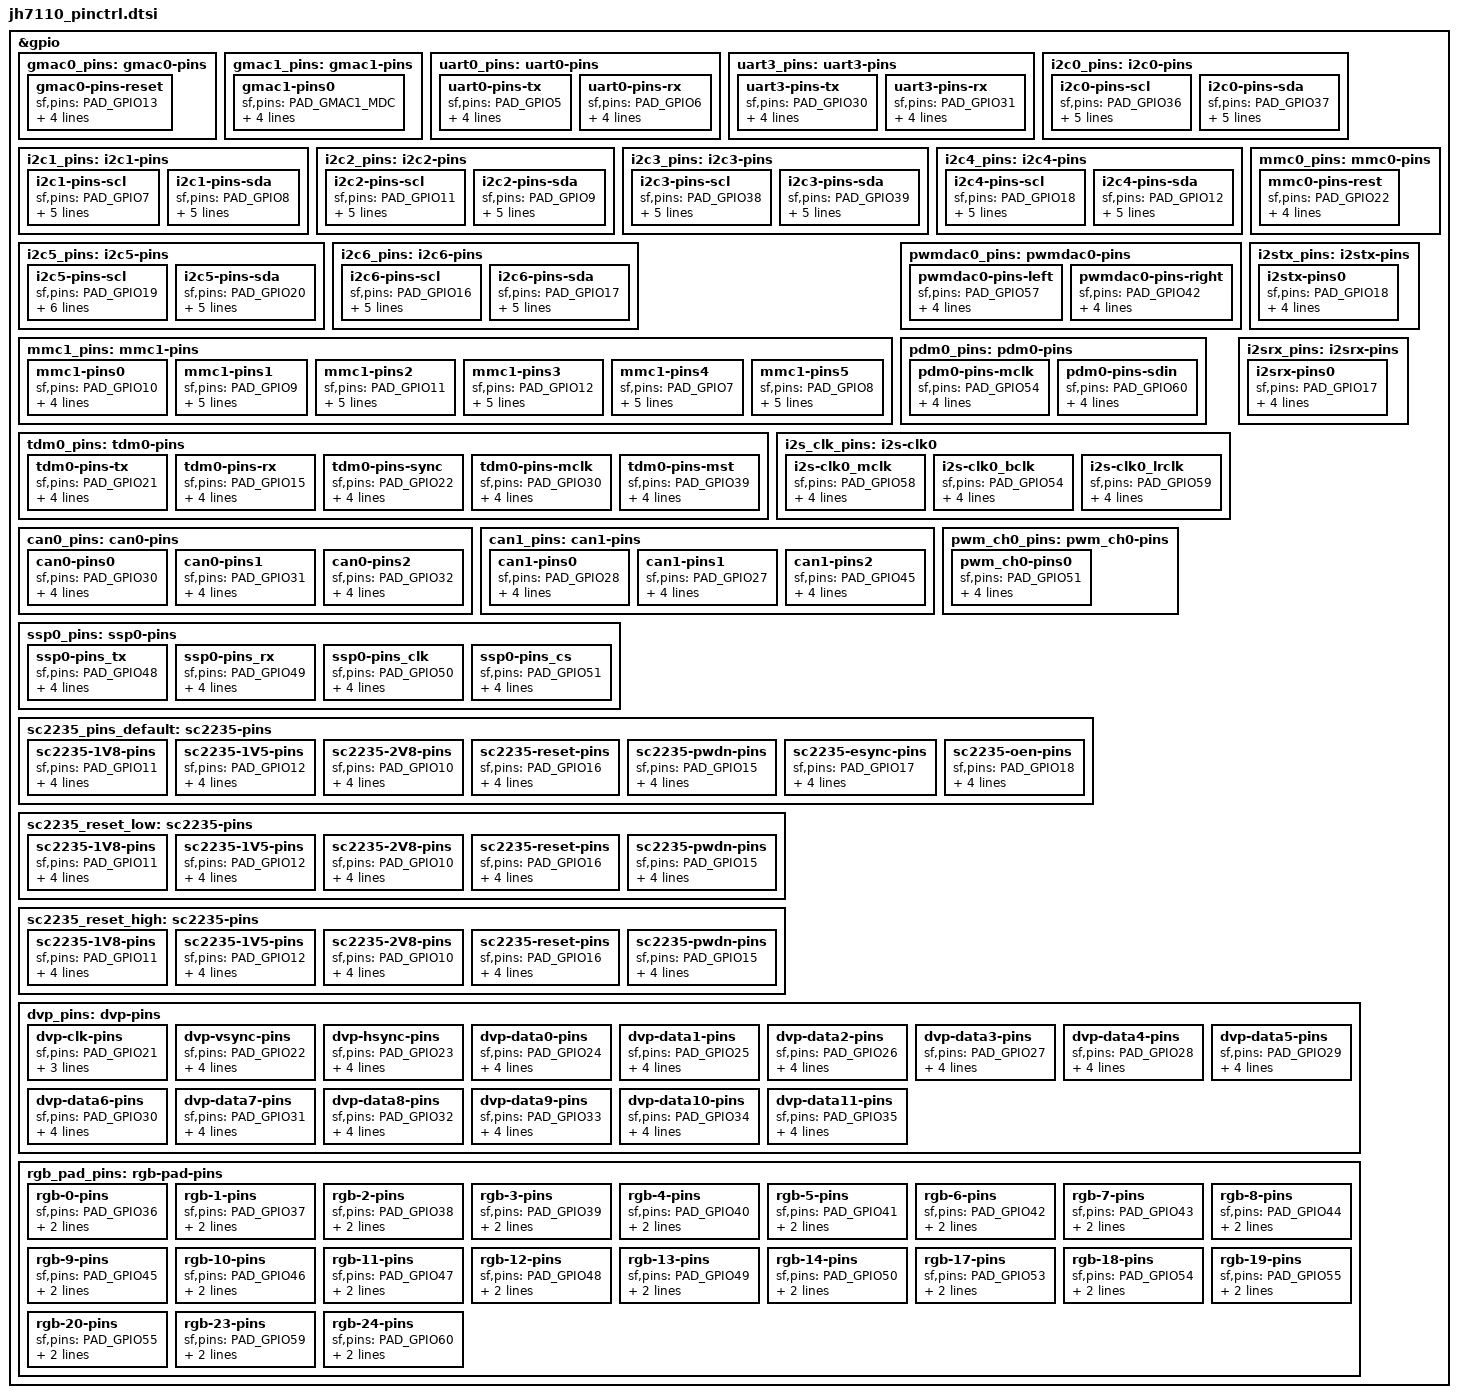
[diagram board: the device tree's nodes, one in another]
// SPDX-License-Identifier: GPL-2.0 OR MIT
/*
 * Copyright (C) 2022 StarFive Technology Co., Ltd.
 */

#include <dt-bindings/gpio/gpio.h>
#include <dt-bindings/pinctrl/starfive,jh7110-pinfunc.h>

&gpio {
	gmac0_pins: gmac0-pins {
		gmac0-pins-reset {
			sf,pins = <PAD_GPIO13>;
			sf,pinmux = <PAD_GPIO13_FUNC_SEL 0>;
			sf,pin-ioconfig = <IO(GPIO_IE(1)|(GPIO_PU(1)))>;
			sf,pin-gpio-dout = <GPO_HIGH>;
			sf,pin-gpio-doen = <OEN_LOW>;
		};
	};

	gmac1_pins: gmac1-pins {
		gmac1-pins0 {
			sf,pins = <PAD_GMAC1_MDC>;
			sf,pin-ioconfig = <IO(GPIO_IE(1)|GPIO_SMT(1)|GPIO_DS(3))>;
			sf,pin-syscon = <PADCFG_PAD_GMAC1_MDC_SYSCON IO_3_3V>;
		};
	};

	uart0_pins: uart0-pins {
		uart0-pins-tx {
			sf,pins = <PAD_GPIO5>;
			sf,pinmux = <PAD_GPIO5_FUNC_SEL 0>;
			sf,pin-ioconfig = <IO(GPIO_IE(1)|GPIO_DS(3))>;
			sf,pin-gpio-dout = <GPO_UART0_SOUT>;
			sf,pin-gpio-doen = <OEN_LOW>;
		};

		uart0-pins-rx {
			sf,pins = <PAD_GPIO6>;
			sf,pinmux = <PAD_GPIO6_FUNC_SEL 0>;
			sf,pin-ioconfig = <IO(GPIO_IE(1)|GPIO_PU(1))>;
			sf,pin-gpio-doen = <OEN_HIGH>;
			sf,pin-gpio-din =  <GPI_UART0_SIN>;
		};
	};

	uart3_pins: uart3-pins {
		uart3-pins-tx {
			sf,pins = <PAD_GPIO30>;
			sf,pinmux = <PAD_GPIO30_FUNC_SEL 0>;
			sf,pin-ioconfig = <IO(GPIO_IE(1)|GPIO_DS(3))>;
			sf,pin-gpio-dout = <GPO_UART3_SOUT>;
			sf,pin-gpio-doen = <OEN_LOW>;
		};

		uart3-pins-rx {
			sf,pins = <PAD_GPIO31>;
			sf,pinmux = <PAD_GPIO31_FUNC_SEL 0>;
			sf,pin-ioconfig = <IO(GPIO_IE(1)|GPIO_PU(1))>;
			sf,pin-gpio-doen = <OEN_HIGH>;
			sf,pin-gpio-din =  <GPI_UART3_SIN>;
		};
	};

	i2c0_pins: i2c0-pins {
		i2c0-pins-scl {
			sf,pins = <PAD_GPIO36>;
			sf,pinmux = <PAD_GPIO36_FUNC_SEL 0>;
			sf,pin-ioconfig = <IO(GPIO_IE(1)|(GPIO_PU(1)))>;
			sf,pin-gpio-dout = <GPO_LOW>;
			sf,pin-gpio-doen = <OEN_I2C0_IC_CLK_OE>;
			sf,pin-gpio-din =  <GPI_I2C0_IC_CLK_IN_A>;
		};

		i2c0-pins-sda {
			sf,pins = <PAD_GPIO37>;
			sf,pinmux = <PAD_GPIO37_FUNC_SEL 0>;
			sf,pin-ioconfig = <IO(GPIO_IE(1)|(GPIO_PU(1)))>;
			sf,pin-gpio-dout = <GPO_LOW>;
			sf,pin-gpio-doen = <OEN_I2C0_IC_DATA_OE>;
			sf,pin-gpio-din =  <GPI_I2C0_IC_DATA_IN_A>;
		};
	};

	i2c1_pins: i2c1-pins {
		i2c1-pins-scl {
			sf,pins = <PAD_GPIO7>;
			sf,pinmux = <PAD_GPIO7_FUNC_SEL 0>;
			sf,pin-ioconfig = <IO(GPIO_IE(1)|(GPIO_PU(1)))>;
			sf,pin-gpio-dout = <GPO_LOW>;
			sf,pin-gpio-doen = <OEN_I2C1_IC_CLK_OE>;
			sf,pin-gpio-din =  <GPI_I2C1_IC_CLK_IN_A>;
		};

		i2c1-pins-sda {
			sf,pins = <PAD_GPIO8>;
			sf,pinmux = <PAD_GPIO8_FUNC_SEL 0>;
			sf,pin-ioconfig = <IO(GPIO_IE(1)|(GPIO_PU(1)))>;
			sf,pin-gpio-dout = <GPO_LOW>;
			sf,pin-gpio-doen = <OEN_I2C1_IC_DATA_OE>;
			sf,pin-gpio-din =  <GPI_I2C1_IC_DATA_IN_A>;
		};
	};

	i2c2_pins: i2c2-pins {
		i2c2-pins-scl {
			sf,pins = <PAD_GPIO11>;
			sf,pinmux = <PAD_GPIO11_FUNC_SEL 0>;
			sf,pin-ioconfig = <IO(GPIO_IE(1)|(GPIO_PU(1)))>;
			sf,pin-gpio-dout = <GPO_LOW>;
			sf,pin-gpio-doen = <OEN_I2C2_IC_CLK_OE>;
			sf,pin-gpio-din =  <GPI_I2C2_IC_CLK_IN_A>;
		};

		i2c2-pins-sda {
			sf,pins = <PAD_GPIO9>;
			sf,pinmux = <PAD_GPIO9_FUNC_SEL 0>;
			sf,pin-ioconfig = <IO(GPIO_IE(1)|(GPIO_PU(1)))>;
			sf,pin-gpio-dout = <GPO_LOW>;
			sf,pin-gpio-doen = <OEN_I2C2_IC_DATA_OE>;
			sf,pin-gpio-din =  <GPI_I2C2_IC_DATA_IN_A>;
		};
	};

	i2c3_pins: i2c3-pins {
		i2c3-pins-scl {
			sf,pins = <PAD_GPIO38>;
			sf,pinmux = <PAD_GPIO38_FUNC_SEL 0>;
			sf,pin-ioconfig = <IO(GPIO_IE(1)|(GPIO_PU(1)))>;
			sf,pin-gpio-dout = <GPO_LOW>;
			sf,pin-gpio-doen = <OEN_I2C3_IC_CLK_OE>;
			sf,pin-gpio-din =  <GPI_I2C3_IC_CLK_IN_A>;
		};

		i2c3-pins-sda {
			sf,pins = <PAD_GPIO39>;
			sf,pinmux = <PAD_GPIO39_FUNC_SEL 0>;
			sf,pin-ioconfig = <IO(GPIO_IE(1)|(GPIO_PU(1)))>;
			sf,pin-gpio-dout = <GPO_LOW>;
			sf,pin-gpio-doen = <OEN_I2C3_IC_DATA_OE>;
			sf,pin-gpio-din =  <GPI_I2C3_IC_DATA_IN_A>;
		};
	};

	i2c4_pins: i2c4-pins {
		i2c4-pins-scl {
			sf,pins = <PAD_GPIO18>;
			sf,pinmux = <PAD_GPIO18_FUNC_SEL 0>;
			sf,pin-ioconfig = <IO(GPIO_IE(1)|(GPIO_PU(1)))>;
			sf,pin-gpio-dout = <GPO_LOW>;
			sf,pin-gpio-doen = <OEN_I2C4_IC_CLK_OE>;
			sf,pin-gpio-din =  <GPI_I2C4_IC_CLK_IN_A>;
		};

		i2c4-pins-sda {
			sf,pins = <PAD_GPIO12>;
			sf,pinmux = <PAD_GPIO12_FUNC_SEL 0>;
			sf,pin-ioconfig = <IO(GPIO_IE(1)|(GPIO_PU(1)))>;
			sf,pin-gpio-dout = <GPO_LOW>;
			sf,pin-gpio-doen = <OEN_I2C4_IC_DATA_OE>;
			sf,pin-gpio-din =  <GPI_I2C4_IC_DATA_IN_A>;
		};
	};

	i2c5_pins: i2c5-pins {
		i2c5-pins-scl {
			sf,pins = <PAD_GPIO19>;
			sf,pinmux = <PAD_GPIO19_FUNC_SEL 0>;
			sf,pin-ioconfig = <genIO(GPIO_IE(1)|(GPIO_PU(1)))>;
			sf,pin-gpio-dout = <GPO_LOW>;
			sf,pin-gpio-doen = <OEN_I2C5_IC_CLK_OE>;
			sf,pin-gpio-din =  <GPI_I2C5_IC_CLK_IN_A>;
		};

		i2c5-pins-sda {
			sf,pins = <PAD_GPIO20>;
			sf,pinmux = <PAD_GPIO20_FUNC_SEL 0>;
			sf,pin-ioconfig = <IO(GPIO_IE(1)|(GPIO_PU(1)))>;
			sf,pin-gpio-dout = <GPO_LOW>;
			sf,pin-gpio-doen = <OEN_I2C5_IC_DATA_OE>;
			sf,pin-gpio-din =  <GPI_I2C5_IC_DATA_IN_A>;
		};
	};

	i2c6_pins: i2c6-pins {
		i2c6-pins-scl {
			sf,pins = <PAD_GPIO16>;
			sf,pinmux = <PAD_GPIO16_FUNC_SEL 0>;
			sf,pin-ioconfig = <IO(GPIO_IE(1)|(GPIO_PU(1)))>;
			sf,pin-gpio-dout = <GPO_LOW>;
			sf,pin-gpio-doen = <OEN_I2C6_IC_CLK_OE>;
			sf,pin-gpio-din =  <GPI_I2C6_IC_CLK_IN_A>;
		};

		i2c6-pins-sda {
			sf,pins = <PAD_GPIO17>;
			sf,pinmux = <PAD_GPIO17_FUNC_SEL 0>;
			sf,pin-ioconfig = <IO(GPIO_IE(1)|(GPIO_PU(1)))>;
			sf,pin-gpio-dout = <GPO_LOW>;
			sf,pin-gpio-doen = <OEN_I2C6_IC_DATA_OE>;
			sf,pin-gpio-din =  <GPI_I2C6_IC_DATA_IN_A>;
		};
	};

	mmc0_pins: mmc0-pins {
		 mmc0-pins-rest {
			sf,pins = <PAD_GPIO22>;
			sf,pinmux = <PAD_GPIO22_FUNC_SEL 0>;
			sf,pin-ioconfig = <IO(GPIO_IE(1)|(GPIO_PU(1)))>;
			sf,pin-gpio-dout = <GPO_SDIO0_RST_N>;
			sf,pin-gpio-doen = <OEN_LOW>;
		};
	};

	mmc1_pins: mmc1-pins {
		 mmc1-pins0 {
			sf,pins = <PAD_GPIO10>;
			sf,pinmux = <PAD_GPIO10_FUNC_SEL 0>;
			sf,pin-ioconfig = <IO(GPIO_IE(1)|(GPIO_PU(1)))>;
			sf,pin-gpio-dout = <GPO_SDIO1_CCLK_OUT>;
			sf,pin-gpio-doen = <OEN_LOW>;
		};

		mmc1-pins1 {
			sf,pins = <PAD_GPIO9>;
			sf,pinmux = <PAD_GPIO9_FUNC_SEL 0>;
			sf,pin-ioconfig = <IO(GPIO_IE(1)|(GPIO_PU(1)))>;
			sf,pin-gpio-dout = <GPO_SDIO1_CCMD_OUT>;
			sf,pin-gpio-doen = <OEN_SDIO1_CCMD_OUT_EN>;
			sf,pin-gpio-din =  <GPI_SDIO1_CCMD_IN>;
		};

		mmc1-pins2 {
			sf,pins = <PAD_GPIO11>;
			sf,pinmux = <PAD_GPIO11_FUNC_SEL 0>;
			sf,pin-ioconfig = <IO(GPIO_IE(1)|(GPIO_PU(1)))>;
			sf,pin-gpio-dout = <GPO_SDIO1_CDATA_OUT_0>;
			sf,pin-gpio-doen = <OEN_SDIO1_CDATA_OUT_EN_0>;
			sf,pin-gpio-din =  <GPI_SDIO1_CDATA_IN_0>;
		};

		mmc1-pins3 {
			sf,pins = <PAD_GPIO12>;
			sf,pinmux = <PAD_GPIO12_FUNC_SEL 0>;
			sf,pin-ioconfig = <IO(GPIO_IE(1)|(GPIO_PU(1)))>;
			sf,pin-gpio-dout = <GPO_SDIO1_CDATA_OUT_1>;
			sf,pin-gpio-doen = <OEN_SDIO1_CDATA_OUT_EN_1>;
			sf,pin-gpio-din =  <GPI_SDIO1_CDATA_IN_1>;
		};

		mmc1-pins4 {
			sf,pins = <PAD_GPIO7>;
			sf,pinmux = <PAD_GPIO7_FUNC_SEL 0>;
			sf,pin-ioconfig = <IO(GPIO_IE(1)|(GPIO_PU(1)))>;
			sf,pin-gpio-dout = <GPO_SDIO1_CDATA_OUT_2>;
			sf,pin-gpio-doen = <OEN_SDIO1_CDATA_OUT_EN_2>;
			sf,pin-gpio-din =  <GPI_SDIO1_CDATA_IN_2>;
		};

		mmc1-pins5 {
			sf,pins = <PAD_GPIO8>;
			sf,pinmux = <PAD_GPIO8_FUNC_SEL 0>;
			sf,pin-ioconfig = <IO(GPIO_IE(1)|(GPIO_PU(1)))>;
			sf,pin-gpio-dout = <GPO_SDIO1_CDATA_OUT_3>;
			sf,pin-gpio-doen = <OEN_SDIO1_CDATA_OUT_EN_3>;
			sf,pin-gpio-din =  <GPI_SDIO1_CDATA_IN_3>;
		};
	};

	pwmdac0_pins: pwmdac0-pins {
		pwmdac0-pins-left {
			sf,pins = <PAD_GPIO57>;
			sf,pinmux = <PAD_GPIO57_FUNC_SEL 0>;
			sf,pin-ioconfig = <IO(GPIO_IE(1)|(GPIO_PU(1)))>;
			sf,pin-gpio-dout = <GPO_PWMDAC0_LEFT_OUTPUT>;
			sf,pin-gpio-doen = <OEN_LOW>;
		};

		pwmdac0-pins-right {
			sf,pins = <PAD_GPIO42>;
			sf,pinmux = <PAD_GPIO42_FUNC_SEL 0>;
			sf,pin-ioconfig = <IO(GPIO_IE(1)|(GPIO_PU(1)))>;
			sf,pin-gpio-dout = <GPO_PWMDAC0_RIGHT_OUTPUT>;
			sf,pin-gpio-doen = <OEN_LOW>;
		};
	};

	pdm0_pins: pdm0-pins {
		pdm0-pins-mclk {
			sf,pins = <PAD_GPIO54>;
			sf,pinmux = <PAD_GPIO54_FUNC_SEL 0>;
			sf,pin-ioconfig = <IO(GPIO_IE(1))>;
			sf,pin-gpio-dout = <GPO_PDM_4MIC0_DMIC_MCLK>;
			sf,pin-gpio-doen = <OEN_LOW>;
		};

		pdm0-pins-sdin {
			sf,pins = <PAD_GPIO60>;
			sf,pinmux = <PAD_GPIO60_FUNC_SEL 0>;
			sf,pin-ioconfig = <IO(GPIO_IE(1))>;
			sf,pin-gpio-doen = <OEN_HIGH>;
			sf,pin-gpio-din =  <GPI_PDM_4MIC0_DMIC0_DIN>;
		};
	};

	tdm0_pins: tdm0-pins {
		tdm0-pins-tx {
			sf,pins = <PAD_GPIO21>;
			sf,pinmux = <PAD_GPIO21_FUNC_SEL 0>;
			sf,pin-ioconfig = <IO(GPIO_IE(1))>;
			sf,pin-gpio-dout = <GPO_TDM0_PCM_TXD>;
			sf,pin-gpio-doen = <OEN_LOW>;
		};

		tdm0-pins-rx {
			sf,pins = <PAD_GPIO15>;
			sf,pinmux = <PAD_GPIO15_FUNC_SEL 0>;
			sf,pin-ioconfig = <IO(GPIO_IE(1))>;
			sf,pin-gpio-doen = <OEN_HIGH>;
			sf,pin-gpio-din =  <GPI_TDM0_PCM_RXD>;
		};

		tdm0-pins-sync {
			sf,pins = <PAD_GPIO22>;
			sf,pinmux = <PAD_GPIO22_FUNC_SEL 0>;
			sf,pin-ioconfig = <IO(GPIO_IE(1))>;
			sf,pin-gpio-dout = <GPO_TDM0_PCM_SYNCOUT>;
			sf,pin-gpio-doen = <OEN_LOW>;
		};

		tdm0-pins-mclk {
			sf,pins = <PAD_GPIO30>;
			sf,pinmux = <PAD_GPIO30_FUNC_SEL 0>;
			sf,pin-ioconfig = <IO(GPIO_IE(1))>;
			sf,pin-gpio-dout = <GPO_CRG0_MCLK_OUT>;
			sf,pin-gpio-doen = <OEN_LOW>;
		};

		tdm0-pins-mst {
			sf,pins = <PAD_GPIO39>;
			sf,pinmux = <PAD_GPIO39_FUNC_SEL 0>;
			sf,pin-ioconfig = <IO(GPIO_IE(1))>;
			sf,pin-gpio-dout = <GPO_TDM0_CLK_MST>;
			sf,pin-gpio-doen = <OEN_LOW>;
		};
	};

	i2s_clk_pins: i2s-clk0 {
		i2s-clk0_mclk {
			sf,pins = <PAD_GPIO58>;
			sf,pinmux = <PAD_GPIO58_FUNC_SEL 0>;
			sf,pin-ioconfig = <IO(GPIO_IE(1))>;
			sf,pin-gpio-dout = <GPO_CRG0_MCLK_OUT>;
			sf,pin-gpio-doen = <OEN_LOW>;
		};

		i2s-clk0_bclk {
			sf,pins = <PAD_GPIO54>;
			sf,pinmux = <PAD_GPIO54_FUNC_SEL 0>;
			sf,pin-ioconfig = <IO(GPIO_IE(1))>;
			sf,pin-gpio-dout = <GPO_I2SRX0_BCLK_MST>;
			sf,pin-gpio-doen = <OEN_LOW>;
		};

		i2s-clk0_lrclk {
			sf,pins = <PAD_GPIO59>;
			sf,pinmux = <PAD_GPIO59_FUNC_SEL 0>;
			sf,pin-ioconfig = <IO(GPIO_IE(1))>;
			sf,pin-gpio-dout = <GPO_I2SRX0_LRCK_MST>;
			sf,pin-gpio-doen = <OEN_LOW>;
		};
	};

	i2stx_pins: i2stx-pins {
		i2stx-pins0 {
			sf,pins = <PAD_GPIO18>;
			sf,pinmux = <PAD_GPIO18_FUNC_SEL 0>;
			sf,pin-ioconfig = <IO(GPIO_IE(1))>;
			sf,pin-gpio-dout = <GPO_I2STX_4CH1_SDO0>;
			sf,pin-gpio-doen = <OEN_LOW>;
		};
	};

	i2srx_pins: i2srx-pins {
		i2srx-pins0 {
			sf,pins = <PAD_GPIO17>;
			sf,pinmux = <PAD_GPIO17_FUNC_SEL 0>;
			sf,pin-ioconfig = <IO(GPIO_IE(1))>;
			sf,pin-gpio-doen = <OEN_HIGH>;
			sf,pin-gpio-din =  <GPI_I2SRX0_EXT_SDIN0>;
		};
	};

	can0_pins: can0-pins {
		can0-pins0 {
			sf,pins = <PAD_GPIO30>;
			sf,pinmux = <PAD_GPIO30_FUNC_SEL 0>;
			sf,pin-ioconfig = <IO(GPIO_IE(1))>;
			sf,pin-gpio-dout = <GPO_CAN0_CTRL_TXD>;
			sf,pin-gpio-doen = <OEN_LOW>;
		};

		can0-pins1 {
			sf,pins = <PAD_GPIO31>;
			sf,pinmux = <PAD_GPIO31_FUNC_SEL 0>;
			sf,pin-ioconfig = <IO(GPIO_IE(1))>;
			sf,pin-gpio-doen = <OEN_HIGH>;
			sf,pin-gpio-din =  <GPI_CAN0_CTRL_RXD>;
		};

		can0-pins2 {
			sf,pins = <PAD_GPIO32>;
			sf,pinmux = <PAD_GPIO32_FUNC_SEL 0>;
			sf,pin-ioconfig = <IO(GPIO_IE(1))>;
			sf,pin-gpio-dout = <GPO_CAN0_CTRL_STBY>;
			sf,pin-gpio-doen = <OEN_LOW>;
		};
	};

	can1_pins: can1-pins {
		can1-pins0 {
			sf,pins = <PAD_GPIO28>;
			sf,pinmux = <PAD_GPIO28_FUNC_SEL 0>;
			sf,pin-ioconfig = <IO(GPIO_IE(1))>;
			sf,pin-gpio-dout = <GPO_CAN1_CTRL_TXD>;
			sf,pin-gpio-doen = <OEN_LOW>;
		};

		can1-pins1 {
			sf,pins = <PAD_GPIO27>;
			sf,pinmux = <PAD_GPIO27_FUNC_SEL 0>;
			sf,pin-ioconfig = <IO(GPIO_IE(1))>;
			sf,pin-gpio-doen = <OEN_HIGH>;
			sf,pin-gpio-din =  <GPI_CAN1_CTRL_RXD>;
		};

		can1-pins2 {
			sf,pins = <PAD_GPIO45>;
			sf,pinmux = <PAD_GPIO45_FUNC_SEL 0>;
			sf,pin-ioconfig = <IO(GPIO_IE(1))>;
			sf,pin-gpio-dout = <GPO_CAN1_CTRL_STBY>;
			sf,pin-gpio-doen = <OEN_LOW>;
		};
	};

	pwm_ch0_pins: pwm_ch0-pins {
		pwm_ch0-pins0 {
			sf,pins = <PAD_GPIO51>;
			sf,pinmux = <PAD_GPIO51_FUNC_SEL 0>;
			sf,pin-ioconfig = <IO(GPIO_IE(1))>;
			sf,pin-gpio-dout = <GPO_PTC0_PWM_0>;
			sf,pin-gpio-doen = <OEN_PTC0_PWM_0_OE_N>;
		};
	};

	ssp0_pins: ssp0-pins {
		ssp0-pins_tx {
			sf,pins = <PAD_GPIO48>;
			sf,pinmux = <PAD_GPIO48_FUNC_SEL 0>;
			sf,pin-ioconfig = <IO(GPIO_IE(1))>;
			sf,pin-gpio-dout = <GPO_SPI0_SSPTXD>;
			sf,pin-gpio-doen = <OEN_LOW>;
		};

		ssp0-pins_rx {
			sf,pins = <PAD_GPIO49>;
			sf,pinmux = <PAD_GPIO49_FUNC_SEL 0>;
			sf,pin-ioconfig = <IO(GPIO_IE(1))>;
			sf,pin-gpio-doen = <OEN_HIGH>;
			sf,pin-gpio-din =  <GPI_SPI0_SSPRXD>;
		};

		ssp0-pins_clk {
			sf,pins = <PAD_GPIO50>;
			sf,pinmux = <PAD_GPIO50_FUNC_SEL 0>;
			sf,pin-ioconfig = <IO(GPIO_IE(1))>;
			sf,pin-gpio-dout = <GPO_SPI0_SSPCLKOUT>;
			sf,pin-gpio-doen = <OEN_LOW>;
		};

		ssp0-pins_cs {
			sf,pins = <PAD_GPIO51>;
			sf,pinmux = <PAD_GPIO51_FUNC_SEL 0>;
			sf,pin-ioconfig = <IO(GPIO_IE(1))>;
			sf,pin-gpio-dout = <GPO_SPI0_SSPFSSOUT>;
			sf,pin-gpio-doen = <OEN_LOW>;
		};
	};

	sc2235_pins_default: sc2235-pins {
		sc2235-1V8-pins {
			sf,pins = <PAD_GPIO11>;
			sf,pinmux = <PAD_GPIO11_FUNC_SEL 0>;
			sf,pin-ioconfig = <IO(GPIO_IE(1))>;
			sf,pin-gpio-dout = <GPO_LOW>;
			sf,pin-gpio-doen = <OEN_LOW>;
		};

		sc2235-1V5-pins {
			sf,pins = <PAD_GPIO12>;
			sf,pinmux = <PAD_GPIO12_FUNC_SEL 0>;
			sf,pin-ioconfig = <IO(GPIO_IE(1))>;
			sf,pin-gpio-dout = <GPO_LOW>;
			sf,pin-gpio-doen = <OEN_LOW>;
		};

		sc2235-2V8-pins {
			sf,pins = <PAD_GPIO10>;
			sf,pinmux = <PAD_GPIO10_FUNC_SEL 0>;
			sf,pin-ioconfig = <IO(GPIO_IE(1))>;
			sf,pin-gpio-dout = <GPO_LOW>;
			sf,pin-gpio-doen = <OEN_LOW>;
		};

		sc2235-reset-pins {
			sf,pins = <PAD_GPIO16>;
			sf,pinmux = <PAD_GPIO16_FUNC_SEL 0>;
			sf,pin-ioconfig = <IO(GPIO_IE(1))>;
			sf,pin-gpio-dout = <GPO_LOW>;
			sf,pin-gpio-doen = <OEN_LOW>;
		};

		sc2235-pwdn-pins {
			sf,pins = <PAD_GPIO15>;
			sf,pinmux = <PAD_GPIO15_FUNC_SEL 0>;
			sf,pin-ioconfig = <IO(GPIO_IE(1))>;
			sf,pin-gpio-dout = <GPO_LOW>;
			sf,pin-gpio-doen = <OEN_LOW>;
		};

		sc2235-esync-pins {
			sf,pins = <PAD_GPIO17>;
			sf,pinmux = <PAD_GPIO17_FUNC_SEL 0>;
			sf,pin-ioconfig = <IO(GPIO_IE(1))>;
			sf,pin-gpio-dout = <GPO_LOW>;
			sf,pin-gpio-doen = <OEN_LOW>;
		};

		sc2235-oen-pins {
			sf,pins = <PAD_GPIO18>;
			sf,pinmux = <PAD_GPIO18_FUNC_SEL 0>;
			sf,pin-ioconfig = <IO(GPIO_IE(1))>;
			sf,pin-gpio-dout = <GPO_LOW>;
			sf,pin-gpio-doen = <OEN_LOW>;
		};
	};

	sc2235_reset_low: sc2235-pins {
		sc2235-1V8-pins {
			sf,pins = <PAD_GPIO11>;
			sf,pinmux = <PAD_GPIO11_FUNC_SEL 0>;
			sf,pin-ioconfig = <IO(GPIO_IE(1))>;
			sf,pin-gpio-dout = <GPO_LOW>;
			sf,pin-gpio-doen = <OEN_LOW>;
		};

		sc2235-1V5-pins {
			sf,pins = <PAD_GPIO12>;
			sf,pinmux = <PAD_GPIO12_FUNC_SEL 0>;
			sf,pin-ioconfig = <IO(GPIO_IE(1))>;
			sf,pin-gpio-dout = <GPO_LOW>;
			sf,pin-gpio-doen = <OEN_LOW>;
		};

		sc2235-2V8-pins {
			sf,pins = <PAD_GPIO10>;
			sf,pinmux = <PAD_GPIO10_FUNC_SEL 0>;
			sf,pin-ioconfig = <IO(GPIO_IE(1))>;
			sf,pin-gpio-dout = <GPO_LOW>;
			sf,pin-gpio-doen = <OEN_LOW>;
		};

		sc2235-reset-pins {
			sf,pins = <PAD_GPIO16>;
			sf,pinmux = <PAD_GPIO16_FUNC_SEL 0>;
			sf,pin-ioconfig = <IO(GPIO_IE(1))>;
			sf,pin-gpio-dout = <GPO_LOW>;
			sf,pin-gpio-doen = <OEN_LOW>;
		};

		sc2235-pwdn-pins {
			sf,pins = <PAD_GPIO15>;
			sf,pinmux = <PAD_GPIO15_FUNC_SEL 0>;
			sf,pin-ioconfig = <IO(GPIO_IE(1))>;
			sf,pin-gpio-dout = <GPO_LOW>;
			sf,pin-gpio-doen = <OEN_LOW>;
		};
	};

	sc2235_reset_high: sc2235-pins {
		sc2235-1V8-pins {
			sf,pins = <PAD_GPIO11>;
			sf,pinmux = <PAD_GPIO11_FUNC_SEL 0>;
			sf,pin-ioconfig = <IO(GPIO_IE(1))>;
			sf,pin-gpio-dout = <GPO_HIGH>;
			sf,pin-gpio-doen = <OEN_LOW>;
		};

		sc2235-1V5-pins {
			sf,pins = <PAD_GPIO12>;
			sf,pinmux = <PAD_GPIO12_FUNC_SEL 0>;
			sf,pin-ioconfig = <IO(GPIO_IE(1))>;
			sf,pin-gpio-dout = <GPO_HIGH>;
			sf,pin-gpio-doen = <OEN_LOW>;
		};

		sc2235-2V8-pins {
			sf,pins = <PAD_GPIO10>;
			sf,pinmux = <PAD_GPIO10_FUNC_SEL 0>;
			sf,pin-ioconfig = <IO(GPIO_IE(1))>;
			sf,pin-gpio-dout = <GPO_HIGH>;
			sf,pin-gpio-doen = <OEN_LOW>;
		};

		sc2235-reset-pins {
			sf,pins = <PAD_GPIO16>;
			sf,pinmux = <PAD_GPIO16_FUNC_SEL 0>;
			sf,pin-ioconfig = <IO(GPIO_IE(1))>;
			sf,pin-gpio-dout = <GPO_HIGH>;
			sf,pin-gpio-doen = <OEN_LOW>;
		};

		sc2235-pwdn-pins {
			sf,pins = <PAD_GPIO15>;
			sf,pinmux = <PAD_GPIO15_FUNC_SEL 0>;
			sf,pin-ioconfig = <IO(GPIO_IE(1))>;
			sf,pin-gpio-dout = <GPO_HIGH>;
			sf,pin-gpio-doen = <OEN_LOW>;
		};
	};

	dvp_pins: dvp-pins {
		dvp-clk-pins {
			sf,pins = <PAD_GPIO21>;
			sf,pinmux = <PAD_GPIO21_FUNC_SEL 2>;
			sf,pin-ioconfig = <IO(GPIO_IE(1))>;
			sf,padmux = <U0_SYS_CRG_DVP_CLK_FUNC_SEL 1>;
		};

		dvp-vsync-pins {
			sf,pins = <PAD_GPIO22>;
			sf,pinmux = <PAD_GPIO22_FUNC_SEL 2>;
			sf,pin-ioconfig = <IO(GPIO_IE(1))>;
			sf,padmux = <U0_DOM_ISP_TOP_U0_VIN_DVP_VVALID_C_FUNC_SEL 1>;
		};

		dvp-hsync-pins {
			sf,pins = <PAD_GPIO23>;
			sf,pinmux = <PAD_GPIO23_FUNC_SEL 2>;
			sf,pin-ioconfig = <IO(GPIO_IE(1))>;
			sf,padmux = <U0_DOM_ISP_TOP_U0_VIN_DVP_HVALID_C_FUNC_SEL 1>;
		};

		dvp-data0-pins {
			sf,pins = <PAD_GPIO24>;
			sf,pinmux = <PAD_GPIO24_FUNC_SEL 2>;
			sf,pin-ioconfig = <IO(GPIO_IE(1))>;
			sf,padmux = <U0_DOM_ISP_TOP_U0_VIN_DVP_DATA_C0_FUNC_SEL 1>;
		};

		dvp-data1-pins {
			sf,pins = <PAD_GPIO25>;
			sf,pinmux = <PAD_GPIO25_FUNC_SEL 2>;
			sf,pin-ioconfig = <IO(GPIO_IE(1))>;
			sf,padmux = <U0_DOM_ISP_TOP_U0_VIN_DVP_DATA_C1_FUNC_SEL 1>;
		};

		dvp-data2-pins {
			sf,pins = <PAD_GPIO26>;
			sf,pinmux = <PAD_GPIO26_FUNC_SEL 2>;
			sf,pin-ioconfig = <IO(GPIO_IE(1))>;
			sf,padmux = <U0_DOM_ISP_TOP_U0_VIN_DVP_DATA_C2_FUNC_SEL 1>;
		};

		dvp-data3-pins {
			sf,pins = <PAD_GPIO27>;
			sf,pinmux = <PAD_GPIO27_FUNC_SEL 2>;
			sf,pin-ioconfig = <IO(GPIO_IE(1))>;
			sf,padmux = <U0_DOM_ISP_TOP_U0_VIN_DVP_DATA_C3_FUNC_SEL 1>;
		};

		dvp-data4-pins {
			sf,pins = <PAD_GPIO28>;
			sf,pinmux = <PAD_GPIO28_FUNC_SEL 2>;
			sf,pin-ioconfig = <IO(GPIO_IE(1))>;
			sf,padmux = <U0_DOM_ISP_TOP_U0_VIN_DVP_DATA_C4_FUNC_SEL 1>;
		};

		dvp-data5-pins {
			sf,pins = <PAD_GPIO29>;
			sf,pinmux = <PAD_GPIO29_FUNC_SEL 2>;
			sf,pin-ioconfig = <IO(GPIO_IE(1))>;
			sf,padmux = <U0_DOM_ISP_TOP_U0_VIN_DVP_DATA_C5_FUNC_SEL 1>;
		};

		dvp-data6-pins {
			sf,pins = <PAD_GPIO30>;
			sf,pinmux = <PAD_GPIO30_FUNC_SEL 2>;
			sf,pin-ioconfig = <IO(GPIO_IE(1))>;
			sf,padmux = <U0_DOM_ISP_TOP_U0_VIN_DVP_DATA_C6_FUNC_SEL 1>;
		};

		dvp-data7-pins {
			sf,pins = <PAD_GPIO31>;
			sf,pinmux = <PAD_GPIO31_FUNC_SEL 2>;
			sf,pin-ioconfig = <IO(GPIO_IE(1))>;
			sf,padmux = <U0_DOM_ISP_TOP_U0_VIN_DVP_DATA_C7_FUNC_SEL 1>;
		};

		dvp-data8-pins {
			sf,pins = <PAD_GPIO32>;
			sf,pinmux = <PAD_GPIO32_FUNC_SEL 2>;
			sf,pin-ioconfig = <IO(GPIO_IE(1))>;
			sf,padmux = <U0_DOM_ISP_TOP_U0_VIN_DVP_DATA_C8_FUNC_SEL 1>;
		};

		dvp-data9-pins {
			sf,pins = <PAD_GPIO33>;
			sf,pinmux = <PAD_GPIO33_FUNC_SEL 2>;
			sf,pin-ioconfig = <IO(GPIO_IE(1))>;
			sf,padmux = <U0_DOM_ISP_TOP_U0_VIN_DVP_DATA_C9_FUNC_SEL 1>;
		};

		dvp-data10-pins {
			sf,pins = <PAD_GPIO34>;
			sf,pinmux = <PAD_GPIO34_FUNC_SEL 2>;
			sf,pin-ioconfig = <IO(GPIO_IE(1))>;
			sf,padmux = <U0_DOM_ISP_TOP_U0_VIN_DVP_DATA_C10_FUNC_SEL 1>;
		};

		dvp-data11-pins {
			sf,pins = <PAD_GPIO35>;
			sf,pinmux = <PAD_GPIO35_FUNC_SEL 2>;
			sf,pin-ioconfig = <IO(GPIO_IE(1) | GPIO_PD(1))>;
			sf,padmux = <U0_DOM_ISP_TOP_U0_VIN_DVP_DATA_C11_FUNC_SEL 1>;
		};
	};

	rgb_pad_pins: rgb-pad-pins {
		rgb-0-pins {
			sf,pins = <PAD_GPIO36>;
			sf,pinmux = <PAD_GPIO36_FUNC_SEL 1>;
			sf,pin-ioconfig = <IO(GPIO_IE(0))>;
		};
		rgb-1-pins {
			sf,pins = <PAD_GPIO37>;
			sf,pinmux = <PAD_GPIO37_FUNC_SEL 1>;
			sf,pin-ioconfig = <IO(GPIO_IE(0))>;
		};
		rgb-2-pins {
			sf,pins = <PAD_GPIO38>;
			sf,pinmux = <PAD_GPIO38_FUNC_SEL 1>;
			sf,pin-ioconfig = <IO(GPIO_IE(0))>;
		};
		rgb-3-pins {
			sf,pins = <PAD_GPIO39>;
			sf,pinmux = <PAD_GPIO39_FUNC_SEL 1>;
			sf,pin-ioconfig = <IO(GPIO_IE(0))>;
		};
		rgb-4-pins {
			sf,pins = <PAD_GPIO40>;
			sf,pinmux = <PAD_GPIO40_FUNC_SEL 1>;
			sf,pin-ioconfig = <IO(GPIO_IE(0))>;
		};
		rgb-5-pins {
			sf,pins = <PAD_GPIO41>;
			sf,pinmux = <PAD_GPIO41_FUNC_SEL 1>;
			sf,pin-ioconfig = <IO(GPIO_IE(0))>;
		};
		rgb-6-pins {
			sf,pins = <PAD_GPIO42>;
			sf,pinmux = <PAD_GPIO42_FUNC_SEL 1>;
			sf,pin-ioconfig = <IO(GPIO_IE(0))>;
		};
		rgb-7-pins {
			sf,pins = <PAD_GPIO43>;
			sf,pinmux = <PAD_GPIO43_FUNC_SEL 1>;
			sf,pin-ioconfig = <IO(GPIO_IE(0))>;
		};
		rgb-8-pins {
			sf,pins = <PAD_GPIO44>;
			sf,pinmux = <PAD_GPIO44_FUNC_SEL 1>;
			sf,pin-ioconfig = <IO(GPIO_IE(0))>;
		};
		rgb-9-pins {
			sf,pins = <PAD_GPIO45>;
			sf,pinmux = <PAD_GPIO45_FUNC_SEL 1>;
			sf,pin-ioconfig = <IO(GPIO_IE(0))>;
		};
		rgb-10-pins {
			sf,pins = <PAD_GPIO46>;
			sf,pinmux = <PAD_GPIO46_FUNC_SEL 1>;
			sf,pin-ioconfig = <IO(GPIO_IE(0))>;
		};
		rgb-11-pins {
			sf,pins = <PAD_GPIO47>;
			sf,pinmux = <PAD_GPIO47_FUNC_SEL 1>;
			sf,pin-ioconfig = <IO(GPIO_IE(0))>;
		};
		rgb-12-pins {
			sf,pins = <PAD_GPIO48>;
			sf,pinmux = <PAD_GPIO48_FUNC_SEL 1>;
			sf,pin-ioconfig = <IO(GPIO_IE(0))>;
		};
		rgb-13-pins {
			sf,pins = <PAD_GPIO49>;
			sf,pinmux = <PAD_GPIO49_FUNC_SEL 1>;
			sf,pin-ioconfig = <IO(GPIO_IE(0))>;
		};
		rgb-14-pins {
			sf,pins = <PAD_GPIO50>;
			sf,pinmux = <PAD_GPIO50_FUNC_SEL 1>;
			sf,pin-ioconfig = <IO(GPIO_IE(0))>;
		};
		//rgb-15-pins {
		//	sf,pins = <PAD_GPIO51>;
		//	sf,pinmux = <PAD_GPIO51_FUNC_SEL 1>;
		//	sf,pin-ioconfig = <IO(GPIO_IE(0))>;
		//	PAD_GPIO51_FUNC_SEL
		//};
		//rgb-16-pins {
		//	sf,pins = <PAD_GPIO52>;
		//	sf,pinmux = <PAD_GPIO52_FUNC_SEL 1>;
		//	sf,pin-ioconfig = <IO(GPIO_IE(0))>;
		//};
		rgb-17-pins {
			sf,pins = <PAD_GPIO53>;
			sf,pinmux = <PAD_GPIO53_FUNC_SEL 1>;
			sf,pin-ioconfig = <IO(GPIO_IE(0))>;
		};
		rgb-18-pins {
			sf,pins = <PAD_GPIO54>;
			sf,pinmux = <PAD_GPIO54_FUNC_SEL 1>;
			sf,pin-ioconfig = <IO(GPIO_IE(0))>;
		};
		rgb-19-pins {
			sf,pins = <PAD_GPIO55>;
			sf,pinmux = <PAD_GPIO38_FUNC_SEL 1>;
			sf,pin-ioconfig = <IO(GPIO_IE(0))>;
		};
		rgb-20-pins {
			sf,pins = <PAD_GPIO55>;
			sf,pinmux = <PAD_GPIO56_FUNC_SEL 1>;
			sf,pin-ioconfig = <IO(GPIO_IE(0))>;
		};
		//rgb-21-pins {
		//	sf,pins = <PAD_GPIO57>;
		//	sf,pinmux = <PAD_GPIO57_FUNC_SEL 1>;
		//	sf,pin-ioconfig = <IO(GPIO_IE(0))>;
		//};
		//rgb-22-pins {
		//	sf,pins = <PAD_GPIO58>;
		//	sf,pinmux = <PAD_GPIO58_FUNC_SEL 1>;
		//	sf,pin-ioconfig = <IO(GPIO_IE(0))>;
		//};
		rgb-23-pins {
			sf,pins = <PAD_GPIO59>;
			sf,pinmux = <PAD_GPIO59_FUNC_SEL 1>;
			sf,pin-ioconfig = <IO(GPIO_IE(0))>;
		};
		rgb-24-pins {
			sf,pins = <PAD_GPIO60>;
			sf,pinmux = <PAD_GPIO60_FUNC_SEL 1>;
			sf,pin-ioconfig = <IO(GPIO_IE(0))>;
		};
		//rgb-25-pins {
		//	sf,pins = <PAD_GPIO61>;
		//	sf,pinmux = <PAD_GPIO61_FUNC_SEL 1>;
		//	sf,pin-ioconfig = <IO(GPIO_IE(0))>;
		//};
		//rgb-26-pins {
		//	sf,pins = <PAD_GPIO62>;
		//	sf,pinmux = <PAD_GPIO62_FUNC_SEL 1>;
		//	sf,pin-ioconfig = <IO(GPIO_IE(0))>;
		//};
		//rgb-27-pins {
		//	sf,pins = <PAD_GPIO63>;
		//	sf,pinmux = <PAD_GPIO63_FUNC_SEL 1>;
		//	sf,pin-ioconfig = <IO(GPIO_IE(0))>;
		//};
	};
};
